# CM4F register map
Registers are read-write, no defined reset value unless marked. A register's access mark holds for its fields unless they carry their own. Offsets are from the block's base; lines under a group give offsets from that group; [hi:lo] are bit positions; {n}, {i} and the like mark numbered series; 'fields as' and 'values as' point back to an identical list; <NAME> marks a mode.

## Memory map
0xE000E100 NVIC size 0x4F0 — Nested Vectored Interrupt Controller
0xE000ED00 SCB size 0x90 — System Control Block
0xE000EF50 CMO size 0x2C — Cache Maintenance Operations

## NVIC — Nested Vectored Interrupt Controller
Base 0xE000E100
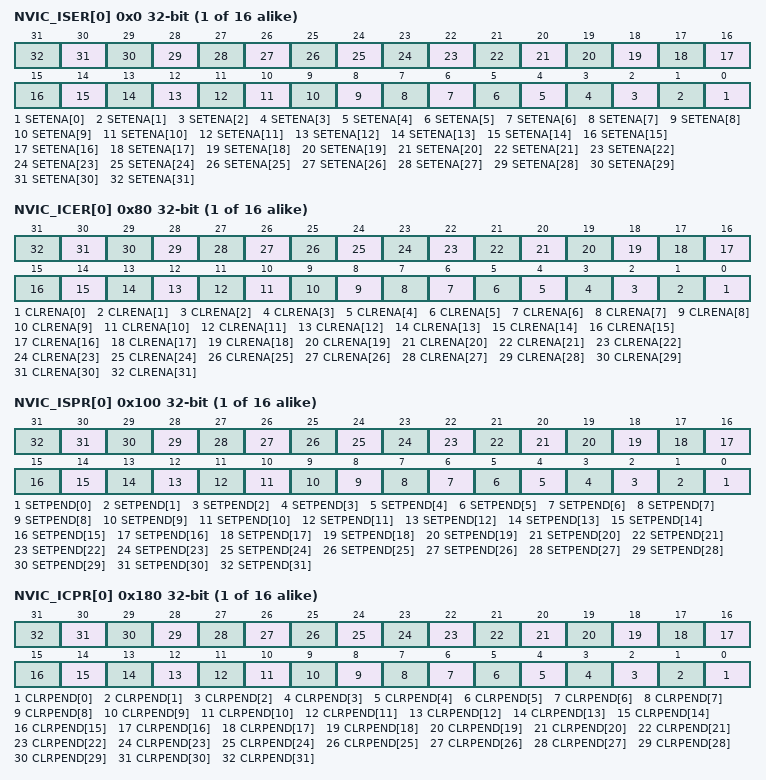
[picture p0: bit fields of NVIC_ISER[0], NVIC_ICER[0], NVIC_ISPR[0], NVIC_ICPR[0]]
{0x0+4i} NVIC_ISER[{i}] (i=0..15) — Interrupt Set-Enable Register enables or reads the enable state of a group of interrupts
  [n] SETENA[{n}] (n=0..31) — For register ISER[n], enables or shows the current enabled state of interrupt (m+(32*n))
    0=On reads, interrupt disabled; 1=On reads, interrupt enabled
{0x80+4i} NVIC_ICER[{i}] (i=0..15) — Interrupt Clear Enable Register disables or reads the enable state of a group of interrupts
  [n] CLRENA[{n}] (n=0..31) — For register ICER[n], disables or shows the current enabled state of interrupt (m+(32*n))
    values as NVIC_ISER[0].SETENA[0]
{0x100+4i} NVIC_ISPR[{i}] (i=0..15) — Interrupt Set Pending Register changes status to pending, or shows the current pending status for a group of interrupts
  [n] SETPEND[{n}] (n=0..31) — For register ISPR[n], changes the state of interrupt (m+(32*n)) to pending, or shows whether the state of the interrupt is pending
    0=On reads, interrupt is not pending; 1=On reads, interrupt is pending
{0x180+4i} NVIC_ICPR[{i}] (i=0..15) — Interrupt Clear Pending Register clears the pending status, or shows the current pending status for a group of interrupts
  [n] CLRPEND[{n}] (n=0..31) — For register ICPR[n], clears the pending state of interrupt (m+(32*n)), or shows whether the state of the interrupt is pending
    values as NVIC_ISPR[0].SETPEND[0]
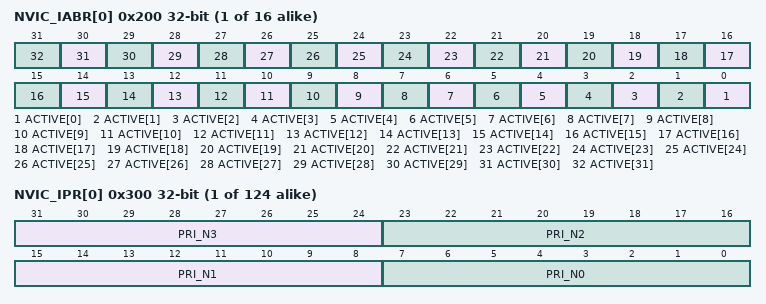
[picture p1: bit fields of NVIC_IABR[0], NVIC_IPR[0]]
{0x200+4i} NVIC_IABR[{i}] (i=0..15) ro — Interrupt Active Bit Register shows whether each interrupt is active for a group of 32 interrupts
  [n] ACTIVE[{n}] (n=0..31) — For register NVIC_IABRn, shows whether interrupt (m+(32*n)) is active
    0=Interrupt not active; 1=Interrupt active
{0x300+4i} NVIC_IPR[{i}] (i=0..123) — Interrupt Priority Register sets or reads interrupt priorities
  [31:24] PRI_N3 — For register NVIC_IPRn, priority of interrupt number 4n+3
  [23:16] PRI_N2 — For register NVIC_IPRn, priority of interrupt number 4n+2
  [15:8] PRI_N1 — For register NVIC_IPRn, priority of interrupt number 4n+1
  [7:0] PRI_N0 — For register NVIC_IPRn, priority of interrupt number 4n

## CMO — Cache Maintenance Operations
Base 0xE000EF50
0x00 ICIALLU wo — Instruction Cache Invalidate All to PoU invalidate all instruction caches to PoU
  [31:0] Ignored — The value written to this field is ignored. Ignored
0x08 ICIMVAU wo — Instruction Cache line Invalidate by Address to PoU invalidate instruction cache line by address to PoU
  [31:0] ADDRESS — Address. Writing to this field initiates the maintenance operation for the address written
0x0C DCIMVAC wo — Data Cache line Invalidate by Address to PoC invalidate data or unified cache line by address to PoC
  fields as ICIMVAU
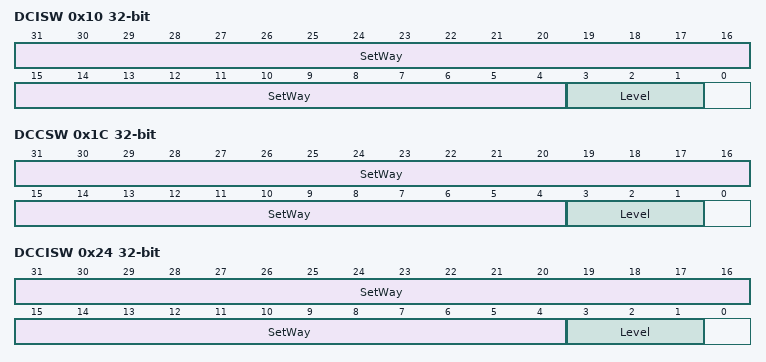
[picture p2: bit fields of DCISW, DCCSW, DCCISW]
0x10 DCISW wo — Data Cache line Invalidate by Set/Way invalidate data or unified cache line by set/way
  [31:4] SetWay — Cache set/way. Contains two fields: Way, bits[31:32-A], the number of the way to operate on
  [3:1] Level — Cache level. Cache level to operate on, minus 1
0x14 DCCMVAU wo — Data Cache line Clean by address to PoU clean data or unified cache line by address to PoU
  fields as ICIMVAU
0x18 DCCMVAC wo — Data Cache line Clean by Address to PoC clean data or unified cache line by address to PoC
  fields as ICIMVAU
0x1C DCCSW wo — Data Cache Clean line by Set/Way clean data or unified cache line by set/way
  [31:4] SetWay — Cache set/way. Contains two fields: Way, bits [31:32-A], the number of the way to operate on
  [3:1] Level — Cache level. Cache level to operate on, minus 1
0x20 DCCIMVAC wo — Data Cache line Clean and Invalidate by Address to PoC clean and invalidate data or unified cache line by address to PoC
  fields as ICIMVAU
0x24 DCCISW wo — Data Cache line Clean and Invalidate by Set/Way clean and invalidate data or unified cache line by set/way
  fields as DCISW
0x28 BPIALL wo — Branch Predictor Invalidate All invalidate all entries from branch predictors
  [31:0] Ignored — Ignored. The value written to this field is ignored
